# APM32F411 register map
Vendor: Geehy; File version: 2024.11.05
CPU: CM4 r1p0, little endian, 3 interrupt priority bits
Registers are 32-bit, read-write, reset 0x0 unless marked. A register's access mark holds for its fields unless they carry their own. Offsets are from the block's base; [hi:lo] are bit positions; {n}, {i} and the like mark numbered series.

## CAN1 — Controller area network
Base 0x40006400
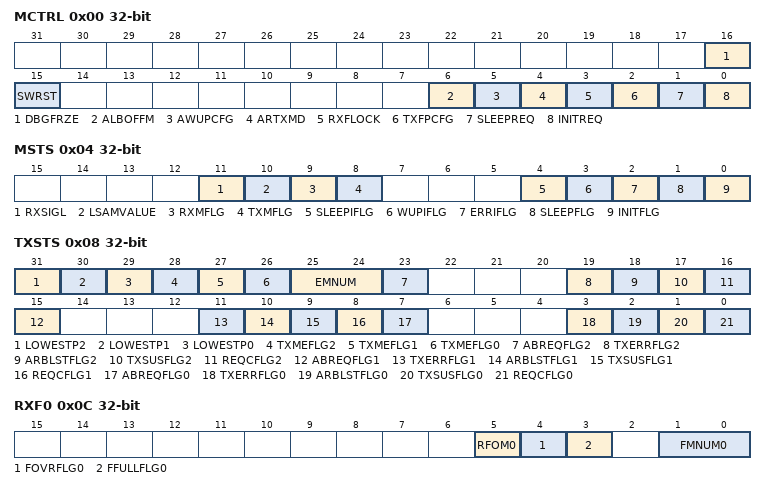
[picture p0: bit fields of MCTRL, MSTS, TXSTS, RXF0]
0x00 MCTRL — CAN Master control register
  [16] DBGFRZE, [15] SWRST, [6] ALBOFFM, [5] AWUPCFG, [4] ARTXMD, [3] RXFLOCK, [2] TXFPCFG, [1] SLEEPREQ, [0] INITREQ
0x04 MSTS access per field — CAN Master States register
  [11] RXSIGL ro, [10] LSAMVALUE ro, [9] RXMFLG ro, [8] TXMFLG ro, [4] SLEEPIFLG rw, [3] WUPIFLG rw, [2] ERRIFLG rw, [1] SLEEPFLG ro, [0] INITFLG ro
0x08 TXSTS access per field — CAN Send States register
  [31] LOWESTP2 ro, [30] LOWESTP1 ro, [29] LOWESTP0 ro, [28] TXMEFLG2 ro, [27] TXMEFLG1 ro, [26] TXMEFLG0 ro, [25:24] EMNUM ro, [23] ABREQFLG2 rw, [19] TXERRFLG2 rw, [18] ARBLSTFLG2 rw, [17] TXSUSFLG2 rw, [16] REQCFLG2 rw, [15] ABREQFLG1 rw, [11] TXERRFLG1 rw, [10] ARBLSTFLG1 rw, [9] TXSUSFLG1 rw, [8] REQCFLG1 rw, [7] ABREQFLG0 rw, [3] TXERRFLG0 rw, [2] ARBLSTFLG0 rw, [1] TXSUSFLG0 rw, [0] REQCFLG0 rw
0x0C RXF0 access per field — CAN Receive FIFO 0 register
  [5] RFOM0 rw, [4] FOVRFLG0 rw, [3] FFULLFLG0 rw, [1:0] FMNUM0 ro
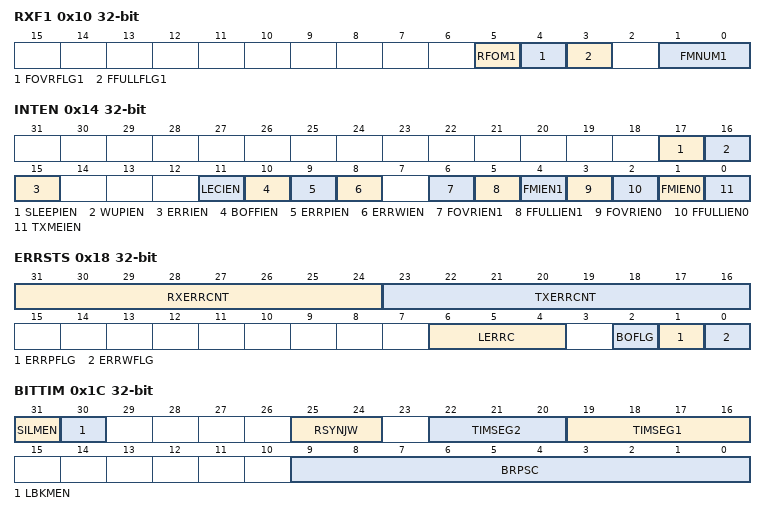
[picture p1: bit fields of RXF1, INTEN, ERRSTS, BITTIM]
0x10 RXF1 access per field — CAN Receive FIFO 1 register
  [5] RFOM1 rw, [4] FOVRFLG1 rw, [3] FFULLFLG1 rw, [1:0] FMNUM1 ro
0x14 INTEN — CAN Interrupts register
  [17] SLEEPIEN, [16] WUPIEN, [15] ERRIEN, [11] LECIEN, [10] BOFFIEN, [9] ERRPIEN, [8] ERRWIEN, [6] FOVRIEN1, [5] FFULLIEN1, [4] FMIEN1, [3] FOVRIEN0, [2] FFULLIEN0, [1] FMIEN0, [0] TXMEIEN
0x18 ERRSTS access per field — CAN Error States register
  [31:24] RXERRCNT ro, [23:16] TXERRCNT ro, [6:4] LERRC rw, [2] BOFLG ro, [1] ERRPFLG ro, [0] ERRWFLG ro
0x1C BITTIM — CAN Bit Time register
  [31] SILMEN, [30] LBKMEN, [25:24] RSYNJW, [22:20] TIMSEG2, [19:16] TIMSEG1, [9:0] BRPSC
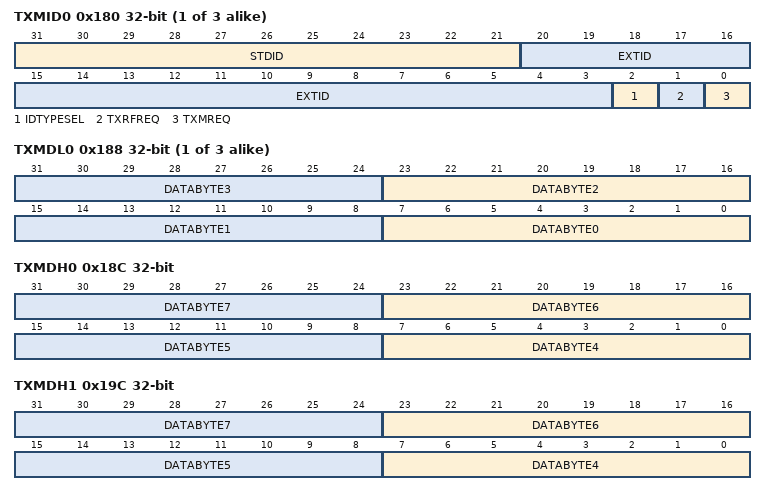
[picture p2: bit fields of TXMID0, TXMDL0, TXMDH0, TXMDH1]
{0x180+0x10*i} TXMID{i} (i=0..2) — CAN Each mailbox contains the sending mailbox identifier register {i}
  [31:21] STDID, [20:3] EXTID, [2] IDTYPESEL, [1] TXRFREQ, [0] TXMREQ
{0x184+0x10*i} TXDLEN{i} (i=0..2) — CAN Send the mailbox data length and timestamp register {i}
  [3:0] DLCODE
{0x188+0x10*i} TXMDL{i} (i=0..2) — CAN Send mailbox low byte data register {i}
  [8n+7:8n] DATABYTE{n} (n=0..3)
0x18C TXMDH0 — CAN Send mailbox High byte data register 0
  [8n-25:8n-32] DATABYTE{n} (n=4..7)
0x19C TXMDH1 — CAN Send mailbox High byte data register1
  [8n-25:8n-32] DATABYTE{n} (n=4..7)
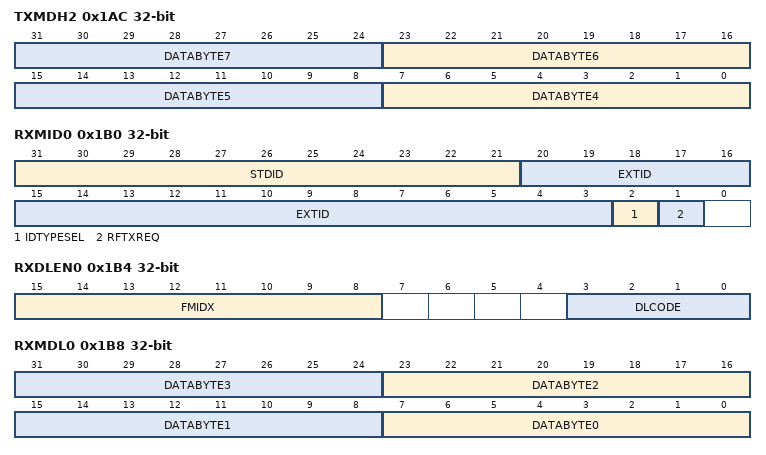
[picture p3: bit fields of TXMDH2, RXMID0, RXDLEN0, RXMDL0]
0x1AC TXMDH2 — CAN Send mailbox High byte data register2
  [8n-25:8n-32] DATABYTE{n} (n=4..7)
0x1B0 RXMID0 ro — CAN Each mailbox contains the receive mailbox identifier register 0
  [31:21] STDID, [20:3] EXTID, [2] IDTYPESEL, [1] RFTXREQ
0x1B4 RXDLEN0 ro — CAN receive the mailbox data length and timestamp register 0
  [15:8] FMIDX, [3:0] DLCODE
0x1B8 RXMDL0 ro — CAN receive mailbox low byte data register 0
  [8n+7:8n] DATABYTE{n} (n=0..3) — DATABYTE{n+1}
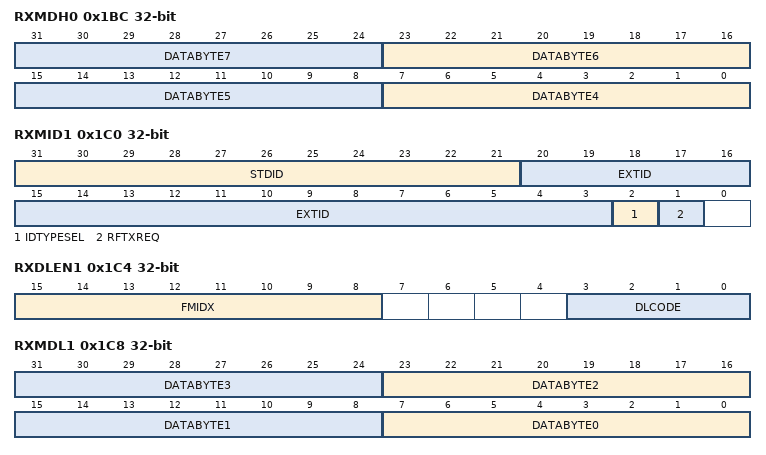
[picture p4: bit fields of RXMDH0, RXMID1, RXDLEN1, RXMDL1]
0x1BC RXMDH0 ro — CAN receive mailbox High byte data register 0
  [8n-25:8n-32] DATABYTE{n} (n=4..7) — DATABYTE{n+1}
0x1C0 RXMID1 ro — CAN Each mailbox contains the receive mailbox identifier register 1
  [31:21] STDID, [20:3] EXTID, [2] IDTYPESEL, [1] RFTXREQ
0x1C4 RXDLEN1 ro — CAN receive the mailbox data length and timestamp register 1
  [15:8] FMIDX, [3:0] DLCODE
0x1C8 RXMDL1 ro — CAN receive mailbox low byte data register 1
  [8n+7:8n] DATABYTE{n} (n=0..3) — DATABYTE{n+1}
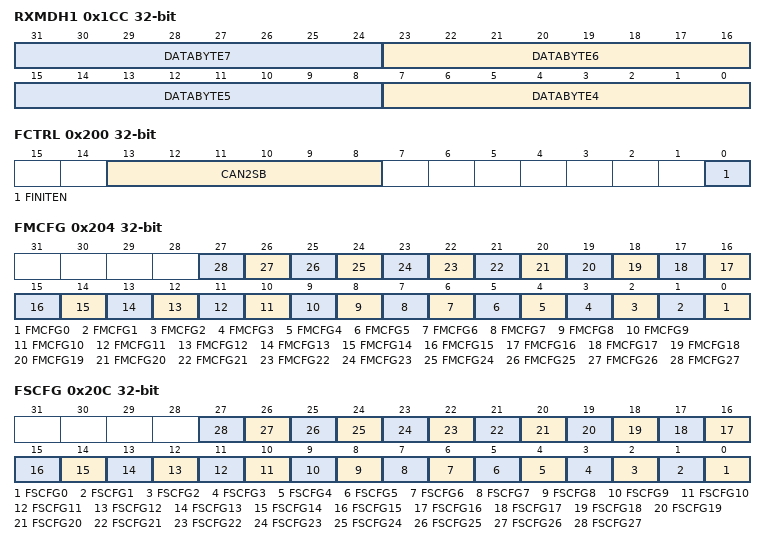
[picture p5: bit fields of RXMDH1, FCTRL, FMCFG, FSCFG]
0x1CC RXMDH1 ro — CAN receive mailbox High byte data register 1
  [8n-25:8n-32] DATABYTE{n} (n=4..7) — DATABYTE{n+1}
0x200 FCTRL — CAN Filter the master control register
  [13:8] CAN2SB — CAN2 Start Bank
  [0] FINITEN
0x204 FMCFG — CAN Filter register
  [n] FMCFG{n} (n=0..27) — Filter mode
0x20C FSCFG — CAN Filter bit width register
  [n] FSCFG{n} (n=0..27) — Filter bit
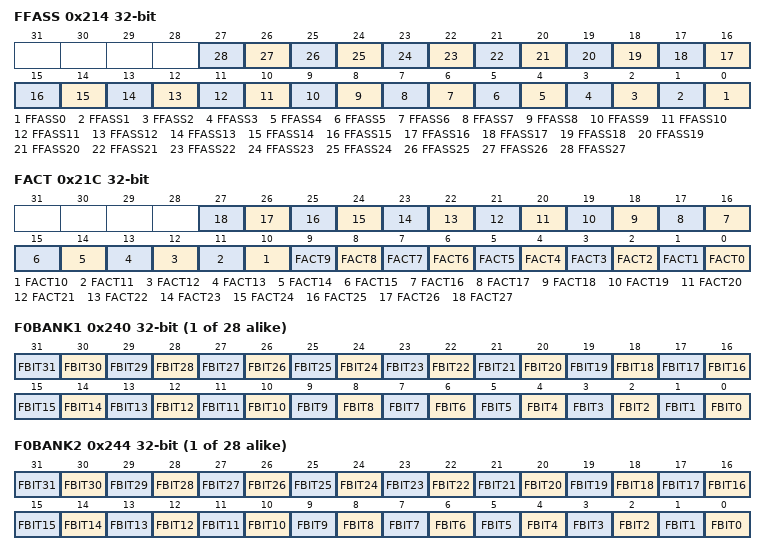
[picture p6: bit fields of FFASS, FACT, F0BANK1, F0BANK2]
0x214 FFASS — CAN Filter FIFO associated registers
  [n] FFASS{n} (n=0..27) — Filter FIFO assignment for filter {n}
0x21C FACT — CAN Filter activation register
  [n] FACT{n} (n=0..27) — Filter active
{0x240+8i} F{i}BANK1 (i=0..27) — Filter bank {i} register 1
  [n] FBIT{n} (n=0..31) — Filter bits
{0x244+8i} F{i}BANK2 (i=0..27) — Filter bank {i} register 2
  [n] FBIT{n} (n=0..31) — Filter bits

## CAN2 — Controller area network
Base 0x40006800
Registers as CAN1; these are added or differ:
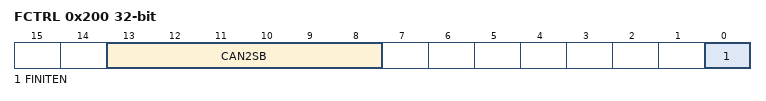
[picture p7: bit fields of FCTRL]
0x200 FCTRL — CAN Filter the master control register
  [13:8] CAN2SB — CAN2 Start Bank
  [0] FINITEN
